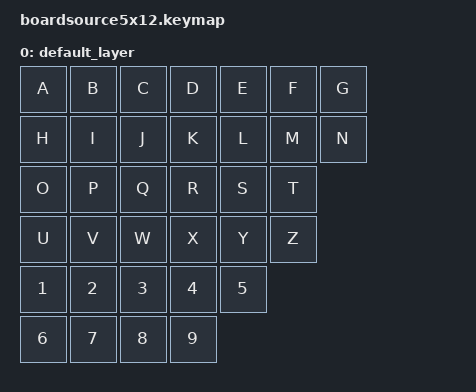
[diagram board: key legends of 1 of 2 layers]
/*
 * Copyright (c) 2021 The ZMK Contributors
 *
 * SPDX-License-Identifier: MIT
 */

#include <behaviors.dtsi>
#include <dt-bindings/zmk/keys.h>
#include <dt-bindings/zmk/bt.h>
#include <dt-bindings/zmk/outputs.h>


/ {
    keymap {
        compatible = "zmk,keymap";

        default_layer {
            bindings = <
                &kp A &kp B &kp C &kp D &kp E &kp F &kp G
                &kp H &kp I &kp J &kp K &kp L &kp M &kp N
                &kp O &kp P &kp Q &kp R &kp S &kp T
                &kp U &kp V &kp W &kp X &kp Y &kp Z
                &kp 1 &kp 2 &kp 3 &kp 4 &kp 5
                &kp 6 &kp 7 &kp 8 &kp 9
            >;
        };
        bt_layer {
            bindings = <
                &kp Z  &bt BT_CLR_ALL    &bootloader  &bt BT_NXT     &out OUT_TOG
            >;
        };

    };
};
